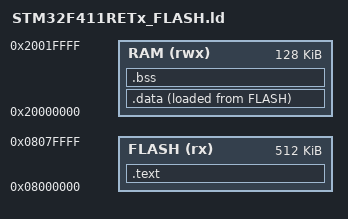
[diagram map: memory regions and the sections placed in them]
/* STM32F411RETx Linker Script */

MEMORY
{
    FLASH (rx)  : ORIGIN = 0x08000000, LENGTH = 512K
    RAM (rwx)   : ORIGIN = 0x20000000, LENGTH = 128K
}

SECTIONS
{
    .text :
    {
        KEEP(*(.vectors))
        *(.text*)
        *(.rodata*)
        . = ALIGN(4);
    } > FLASH

    .data :
    {
        . = ALIGN(4);
        _sdata = .;
        *(.data*)
        . = ALIGN(4);
        _edata = .;
    } > RAM AT > FLASH

    .bss :
    {
        . = ALIGN(4);
        _sbss = .;
        *(.bss*)
        *(COMMON)
        . = ALIGN(4);
        _ebss = .;
    } > RAM

    /DISCARD/ :
    {
        *(.eh_frame)
    }
}

_estack = ORIGIN(RAM) + LENGTH(RAM);
